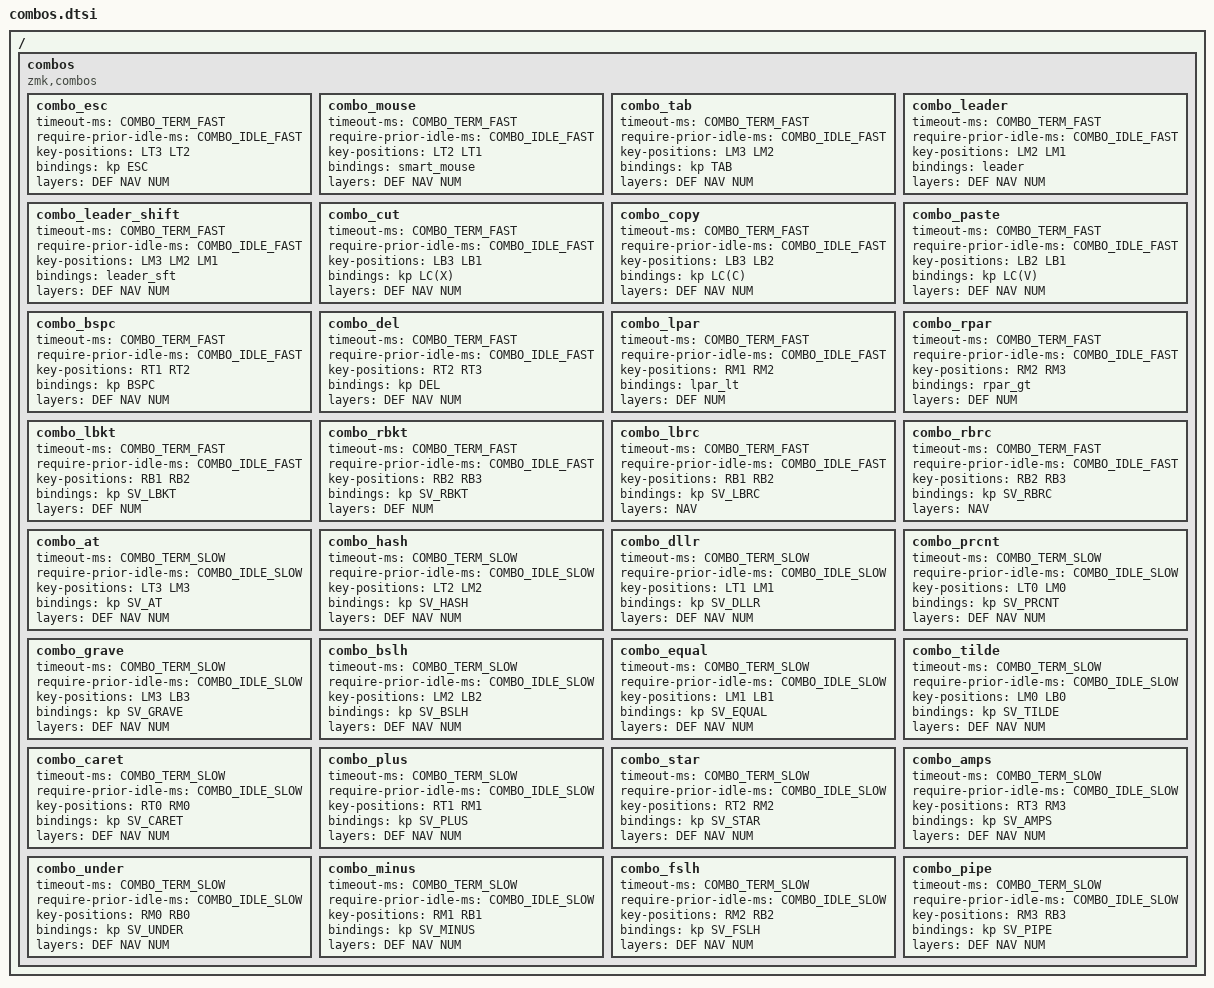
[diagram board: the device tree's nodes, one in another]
/*
 * urob-style symbol/navigation combos, adapted for Swedish keycodes (keys_sv.h).
 *
 * Key positions come from: <zmk-helpers/key-labels/36.h>
 *
 * Layout legend (positions):
 * ┌─────────────────────┐ ┌─────────────────────┐
 * │ LT4 LT3 LT2 LT1 LT0 │ │ RT0 RT1 RT2 RT3 RT4 │
 * │ LM4 LM3 LM2 LM1 LM0 │ │ RM0 RM1 RM2 RM3 RM4 │
 * │ LB4 LB3 LB2 LB1 LB0 │ │ RB0 RB1 RB2 RB3 RB4 │
 * └───────┐ LH2 LH1 LH0 │ │ RH0 RH1 RH2 ┌───────┘
 *         └─────────────┘ └─────────────┘
 */

#define COMBO_TERM_FAST 18
#define COMBO_TERM_SLOW 30

#define COMBO_IDLE_FAST 150
#define COMBO_IDLE_SLOW 50

/ {
  combos {
    compatible = "zmk,combos";

    /* Horizontal combos - left hand */
    combo_esc {
      timeout-ms = <COMBO_TERM_FAST>;
      require-prior-idle-ms = <COMBO_IDLE_FAST>;
      key-positions = <LT3 LT2>;
      bindings = <&kp ESC>;
      layers = <DEF NAV NUM>;
    };

    combo_mouse {
      timeout-ms = <COMBO_TERM_FAST>;
      require-prior-idle-ms = <COMBO_IDLE_FAST>;
      key-positions = <LT2 LT1>;
      bindings = <&smart_mouse>;
      layers = <DEF NAV NUM>;
    };

    combo_tab {
      timeout-ms = <COMBO_TERM_FAST>;
      require-prior-idle-ms = <COMBO_IDLE_FAST>;
      key-positions = <LM3 LM2>;
      bindings = <&kp TAB>;
      layers = <DEF NAV NUM>;
    };

    combo_leader {
      timeout-ms = <COMBO_TERM_FAST>;
      require-prior-idle-ms = <COMBO_IDLE_FAST>;
      key-positions = <LM2 LM1>;
      bindings = <&leader>;
      layers = <DEF NAV NUM>;
    };

    combo_leader_shift {
      timeout-ms = <COMBO_TERM_FAST>;
      require-prior-idle-ms = <COMBO_IDLE_FAST>;
      key-positions = <LM3 LM2 LM1>;
      bindings = <&leader_sft>;
      layers = <DEF NAV NUM>;
    };

    combo_cut {
      timeout-ms = <COMBO_TERM_FAST>;
      require-prior-idle-ms = <COMBO_IDLE_FAST>;
      key-positions = <LB3 LB1>;
      bindings = <&kp LC(X)>;
      layers = <DEF NAV NUM>;
    };

    combo_copy {
      timeout-ms = <COMBO_TERM_FAST>;
      require-prior-idle-ms = <COMBO_IDLE_FAST>;
      key-positions = <LB3 LB2>;
      bindings = <&kp LC(C)>;
      layers = <DEF NAV NUM>;
    };

    combo_paste {
      timeout-ms = <COMBO_TERM_FAST>;
      require-prior-idle-ms = <COMBO_IDLE_FAST>;
      key-positions = <LB2 LB1>;
      bindings = <&kp LC(V)>;
      layers = <DEF NAV NUM>;
    };

    /* Horizontal combos - right hand */
    combo_bspc {
      timeout-ms = <COMBO_TERM_FAST>;
      require-prior-idle-ms = <COMBO_IDLE_FAST>;
      key-positions = <RT1 RT2>;
      bindings = <&kp BSPC>;
      layers = <DEF NAV NUM>;
    };

    combo_del {
      timeout-ms = <COMBO_TERM_FAST>;
      require-prior-idle-ms = <COMBO_IDLE_FAST>;
      key-positions = <RT2 RT3>;
      bindings = <&kp DEL>;
      layers = <DEF NAV NUM>;
    };

    combo_lpar {
      timeout-ms = <COMBO_TERM_FAST>;
      require-prior-idle-ms = <COMBO_IDLE_FAST>;
      key-positions = <RM1 RM2>;
      bindings = <&lpar_lt>;
      layers = <DEF NUM>;
    };

    combo_rpar {
      timeout-ms = <COMBO_TERM_FAST>;
      require-prior-idle-ms = <COMBO_IDLE_FAST>;
      key-positions = <RM2 RM3>;
      bindings = <&rpar_gt>;
      layers = <DEF NUM>;
    };

    combo_lbkt {
      timeout-ms = <COMBO_TERM_FAST>;
      require-prior-idle-ms = <COMBO_IDLE_FAST>;
      key-positions = <RB1 RB2>;
      bindings = <&kp SV_LBKT>;
      layers = <DEF NUM>;
    };

    combo_rbkt {
      timeout-ms = <COMBO_TERM_FAST>;
      require-prior-idle-ms = <COMBO_IDLE_FAST>;
      key-positions = <RB2 RB3>;
      bindings = <&kp SV_RBKT>;
      layers = <DEF NUM>;
    };

    combo_lbrc {
      timeout-ms = <COMBO_TERM_FAST>;
      require-prior-idle-ms = <COMBO_IDLE_FAST>;
      key-positions = <RB1 RB2>;
      bindings = <&kp SV_LBRC>;
      layers = <NAV>;
    };

    combo_rbrc {
      timeout-ms = <COMBO_TERM_FAST>;
      require-prior-idle-ms = <COMBO_IDLE_FAST>;
      key-positions = <RB2 RB3>;
      bindings = <&kp SV_RBRC>;
      layers = <NAV>;
    };

    /* Vertical combos - left hand */
    combo_at {
      timeout-ms = <COMBO_TERM_SLOW>;
      require-prior-idle-ms = <COMBO_IDLE_SLOW>;
      key-positions = <LT3 LM3>;
      bindings = <&kp SV_AT>;
      layers = <DEF NAV NUM>;
    };

    combo_hash {
      timeout-ms = <COMBO_TERM_SLOW>;
      require-prior-idle-ms = <COMBO_IDLE_SLOW>;
      key-positions = <LT2 LM2>;
      bindings = <&kp SV_HASH>;
      layers = <DEF NAV NUM>;
    };

    combo_dllr {
      timeout-ms = <COMBO_TERM_SLOW>;
      require-prior-idle-ms = <COMBO_IDLE_SLOW>;
      key-positions = <LT1 LM1>;
      bindings = <&kp SV_DLLR>;
      layers = <DEF NAV NUM>;
    };

    combo_prcnt {
      timeout-ms = <COMBO_TERM_SLOW>;
      require-prior-idle-ms = <COMBO_IDLE_SLOW>;
      key-positions = <LT0 LM0>;
      bindings = <&kp SV_PRCNT>;
      layers = <DEF NAV NUM>;
    };

    combo_grave {
      timeout-ms = <COMBO_TERM_SLOW>;
      require-prior-idle-ms = <COMBO_IDLE_SLOW>;
      key-positions = <LM3 LB3>;
      bindings = <&kp SV_GRAVE>;
      layers = <DEF NAV NUM>;
    };

    combo_bslh {
      timeout-ms = <COMBO_TERM_SLOW>;
      require-prior-idle-ms = <COMBO_IDLE_SLOW>;
      key-positions = <LM2 LB2>;
      bindings = <&kp SV_BSLH>;
      layers = <DEF NAV NUM>;
    };

    combo_equal {
      timeout-ms = <COMBO_TERM_SLOW>;
      require-prior-idle-ms = <COMBO_IDLE_SLOW>;
      key-positions = <LM1 LB1>;
      bindings = <&kp SV_EQUAL>;
      layers = <DEF NAV NUM>;
    };

    combo_tilde {
      timeout-ms = <COMBO_TERM_SLOW>;
      require-prior-idle-ms = <COMBO_IDLE_SLOW>;
      key-positions = <LM0 LB0>;
      bindings = <&kp SV_TILDE>;
      layers = <DEF NAV NUM>;
    };

    /* Vertical combos - right hand */
    combo_caret {
      timeout-ms = <COMBO_TERM_SLOW>;
      require-prior-idle-ms = <COMBO_IDLE_SLOW>;
      key-positions = <RT0 RM0>;
      bindings = <&kp SV_CARET>;
      layers = <DEF NAV NUM>;
    };

    combo_plus {
      timeout-ms = <COMBO_TERM_SLOW>;
      require-prior-idle-ms = <COMBO_IDLE_SLOW>;
      key-positions = <RT1 RM1>;
      bindings = <&kp SV_PLUS>;
      layers = <DEF NAV NUM>;
    };

    combo_star {
      timeout-ms = <COMBO_TERM_SLOW>;
      require-prior-idle-ms = <COMBO_IDLE_SLOW>;
      key-positions = <RT2 RM2>;
      bindings = <&kp SV_STAR>;
      layers = <DEF NAV NUM>;
    };

    combo_amps {
      timeout-ms = <COMBO_TERM_SLOW>;
      require-prior-idle-ms = <COMBO_IDLE_SLOW>;
      key-positions = <RT3 RM3>;
      bindings = <&kp SV_AMPS>;
      layers = <DEF NAV NUM>;
    };

    combo_under {
      timeout-ms = <COMBO_TERM_SLOW>;
      require-prior-idle-ms = <COMBO_IDLE_SLOW>;
      key-positions = <RM0 RB0>;
      bindings = <&kp SV_UNDER>;
      layers = <DEF NAV NUM>;
    };

    combo_minus {
      timeout-ms = <COMBO_TERM_SLOW>;
      require-prior-idle-ms = <COMBO_IDLE_SLOW>;
      key-positions = <RM1 RB1>;
      bindings = <&kp SV_MINUS>;
      layers = <DEF NAV NUM>;
    };

    combo_fslh {
      timeout-ms = <COMBO_TERM_SLOW>;
      require-prior-idle-ms = <COMBO_IDLE_SLOW>;
      key-positions = <RM2 RB2>;
      bindings = <&kp SV_FSLH>;
      layers = <DEF NAV NUM>;
    };

    combo_pipe {
      timeout-ms = <COMBO_TERM_SLOW>;
      require-prior-idle-ms = <COMBO_IDLE_SLOW>;
      key-positions = <RM3 RB3>;
      bindings = <&kp SV_PIPE>;
      layers = <DEF NAV NUM>;
    };
  };
};

